# PIC32CK2051SG01100 register map
Vendor: Microchip Technology; Series: PIC32CKSG01; File version: 0
CPU: CM33 r0p0, little endian, MPU, FPU, DSP, 3 interrupt priority bits, 158 interrupts, 23 SAU regions
Registers are 32-bit, read-write, reset 0x0 unless marked. A register's access mark holds for its fields unless they carry their own. Offsets are from the block's base; [hi:lo] are bit positions; lines under a group give offsets from that group; {n}, {i} and the like mark numbered series; 'fields as' and 'values as' point back to an identical list.

## EBI — External Bus Interface
Base 0x4502C000; register names take the prefix EBI_
{0x0+0x10*i} CS_X[{i}] (i=0..3) group
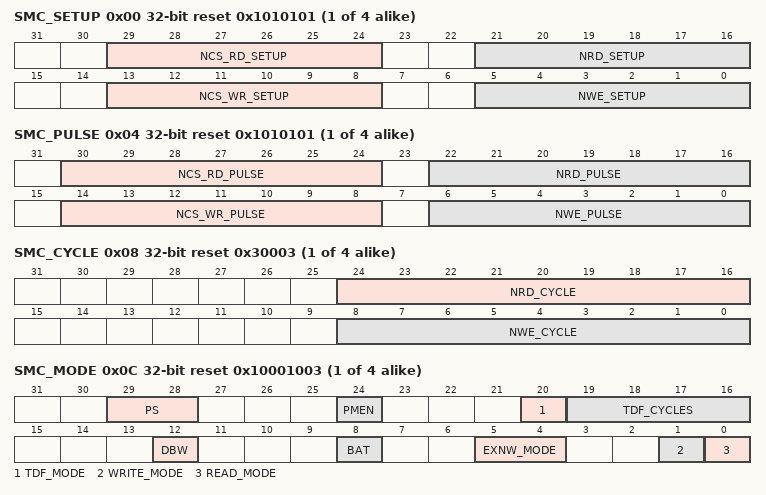
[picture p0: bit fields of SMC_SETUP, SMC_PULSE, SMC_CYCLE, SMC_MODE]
  0x00 SMC_SETUP reset 0x1010101
    [29:24] NCS_RD_SETUP — NCS Setup Length in READ Access
    [21:16] NRD_SETUP — NRD Setup Length
    [13:8] NCS_WR_SETUP — NCS Setup Length in WRITE Access
    [5:0] NWE_SETUP — NWE Setup Length
  0x04 SMC_PULSE reset 0x1010101
    [30:24] NCS_RD_PULSE — NCS Pulse Length in READ Access
    [22:16] NRD_PULSE — NRD Pulse Length
    [14:8] NCS_WR_PULSE — NCS Pulse Length in WRITE Access
    [6:0] NWE_PULSE — NWE Pulse Length
  0x08 SMC_CYCLE reset 0x30003
    [24:16] NRD_CYCLE — Total Read Cycle Length
    [8:0] NWE_CYCLE — Total Write Cycle Length
  0x0C SMC_MODE reset 0x10001003
    [29:28] PS — Page Size
      0=_4_BYTE (4-byte page); 1=_8_BYTE (8-byte page); 2=_16_BYTE (16-byte page); 3=_32_BYTE (32-byte page)
    [24] PMEN — Page Mode Enabled
    [20] TDF_MODE — TDF Optimization
    [19:16] TDF_CYCLES — Data Float Time
    [12] DBW — Data Bus Width
      0=_8_BIT (8-bit Data Bus); 1=_16_BIT (16-bit Data Bus)
    [8] BAT — Byte Access Type
      0=BYTE_SELECT (Byte select access type:- Write operation is controlled using NCS, NWE, NBS0, NBS1.- Read operation is controlled using NCS, NRD, NBS0, NBS1.); 1=BYTE_WRITE (Byte write access type:- Write operation is controlled using NCS, NWR0, NWR1.- Read operation is controlled using NCS and NRD.)
    [5:4] EXNW_MODE — NWAIT Mode
      0=DISABLED (Disabled-The NWAIT input signal is ignored on the corresponding chip select.); 2=FROZEN (Frozen Mode-If asserted, the NWAIT signal freezes the current read or write cycle. After deassertion, the read/write cycle is resumed from the point where it was stopped.); 3=READY (Ready Mode-The NWAIT signal indicates the availability of the external device at the end of the pulse of the controlling read or write signal, to complete the access. If high, the access normally completes. If low, the access is extended until NWAIT returns high.)
    [1] WRITE_MODE
    [0] READ_MODE
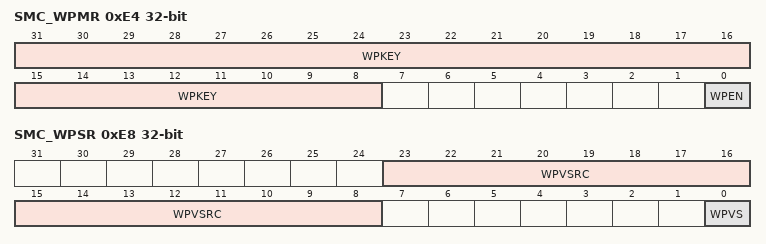
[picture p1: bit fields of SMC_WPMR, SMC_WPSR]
0xE4 SMC_WPMR — SMC Write Protection Mode Register
  [31:8] WPKEY — Write Protection Key
    0x534D43=PASSWD (Writing any other value in this field aborts the write operation of the WPEN bit. Always reads as 0.)
  [0] WPEN — Write Protect Enable
0xE8 SMC_WPSR ro — SMC Write Protection Status Register
  [23:8] WPVSRC — Write Protection Violation Source
  [0] WPVS — Write Protection Violation Status

## EIC — External Interrupt Controller
Base 0x4401A000; register names take the prefix EIC_
Same registers: EIC_SEC 0x4401B000 (register names take the prefix EIC_SEC_)
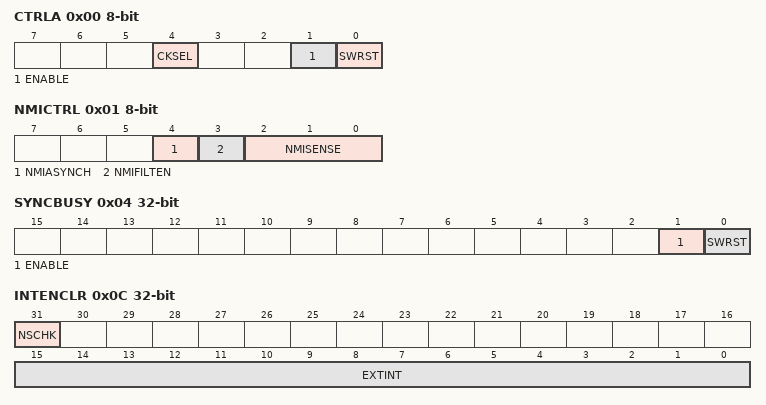
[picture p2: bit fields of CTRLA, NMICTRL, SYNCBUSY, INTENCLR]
0x00 CTRLA 8-bit — Control A
  [4] CKSEL — Clock Selection
    0=CLK_GCLK (Clocked by GCLK); 1=CLK_ULP32K (Clocked by ULP32K)
  [1] ENABLE
  [0] SWRST — Software Reset
0x01 NMICTRL 8-bit — Non-Maskable Interrupt Control
  [4] NMIASYNCH — Asynchronous Edge Detection Mode
    0=SYNC (Edge detection is clock synchronously operated); 1=ASYNC (Edge detection is clock asynchronously operated)
  [3] NMIFILTEN — Non-Maskable Interrupt Filter Enable
  [2:0] NMISENSE — Non-Maskable Interrupt Sense Configuration
    0=NONE (No detection); 1=RISE (Rising-edge detection); 2=FALL (Falling-edge detection); 3=BOTH (Both-edges detection); 4=HIGH (High-level detection); 5=LOW (Low-level detection)
0x02 NMIFLAG 16-bit — Non-Maskable Interrupt Flag Status and Clear
  [0] NMI — Non-Maskable Interrupt
0x04 SYNCBUSY ro — Synchronization Busy
  [1] ENABLE — Enable Synchronization Busy Status
  [0] SWRST — Software Reset Synchronization Busy Status
0x08 EVCTRL — Event Control
  [15:0] EXTINTEO — External Interrupt Event Output Enable
0x0C INTENCLR — Interrupt Enable Clear
  [31] NSCHK — Non-secure Check Interrupt Enable
  [15:0] EXTINT — External Interrupt Enable
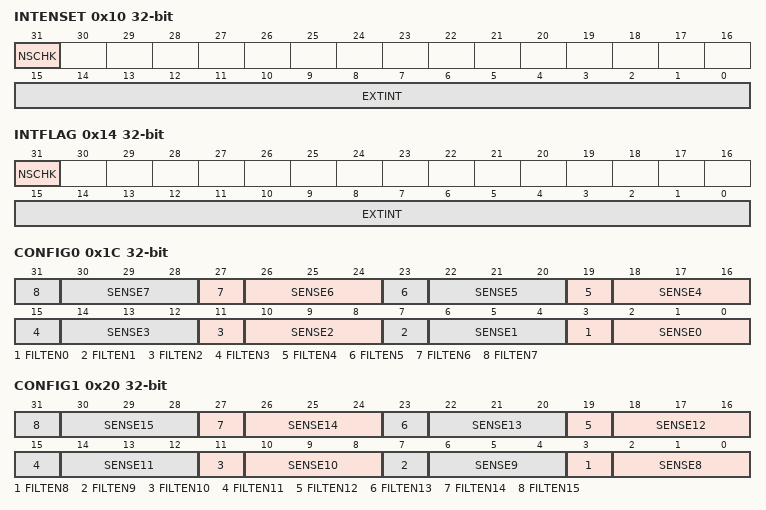
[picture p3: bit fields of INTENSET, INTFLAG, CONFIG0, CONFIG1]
0x10 INTENSET — Interrupt Enable Set
  fields as INTENCLR
0x14 INTFLAG — Interrupt Flag Status and Clear
  [31] NSCHK — Non-secure Check Interrupt
  [15:0] EXTINT — External Interrupt
0x18 ASYNCH — External Interrupt Asynchronous Mode
  [15:0] ASYNCH — Asynchronous Edge Detection Mode
    values as NMICTRL.NMIASYNCH
0x1C CONFIG0 — External Interrupt Sense Configuration
  [4n+3] FILTEN{n} (n=0..7) — Filter Enable {n}
  [4n+2:4n] SENSE{n} (n=0..7) — Input Sense Configuration {n}
    0=NONE (No detection); 1=RISE (Rising edge detection); 2=FALL (Falling edge detection); 3=BOTH (Both edges detection); 4=HIGH (High level detection); 5=LOW (Low level detection)
0x20 CONFIG1 — External Interrupt Sense Configuration
  [4n-29] FILTEN{n} (n=8..15) — Filter Enable {n}
  [4n-30:4n-32] SENSE{n} (n=8..15) — Input Sense Configuration {n}
    values as CONFIG0.SENSE0
0x30 DEBOUNCEN — Debouncer Enable
  [15:0] DEBOUNCEN
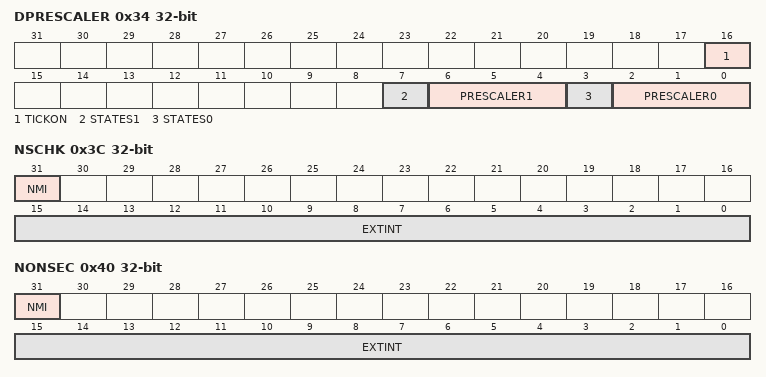
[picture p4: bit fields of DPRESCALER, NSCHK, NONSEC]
0x34 DPRESCALER — Debouncer Prescaler
  [16] TICKON — Pin Sampler frequency selection
    0=CLK_GCLK_EIC (Clocked by GCLK); 1=CLK_LFREQ (Clocked by Low Frequency Clock)
  [7] STATES1 — Debouncer number of states
    0=LFREQ3 (3 low frequency samples); 1=LFREQ7 (7 low frequency samples)
  [6:4] PRESCALER1 — Debouncer Prescaler
    0=DIV2 (EIC clock divided by 2); 1=DIV4 (EIC clock divided by 4); 2=DIV8 (EIC clock divided by 8); 3=DIV16 (EIC clock divided by 16); 4=DIV32 (EIC clock divided by 32); 5=DIV64 (EIC clock divided by 64); 6=DIV128 (EIC clock divided by 128); 7=DIV256 (EIC clock divided by 256)
  [3] STATES0 — Debouncer number of states
    values as STATES1
  [2:0] PRESCALER0 — Debouncer Prescaler
    values as PRESCALER1
0x38 PINSTATE ro
  [15:0] PINSTATE
0x3C NSCHK — Non-secure Interrupt Check Enable
  [31] NMI — Non-Maskable External Interrupt Nonsecure Check Enable
  [15:0] EXTINT — External Interrupt Nonsecure Check Enable
0x40 NONSEC — Non-secure Interrupt
  [31] NMI — Non-Maskable Interrupt Nonsecure Enable
  [15:0] EXTINT — External Interrupt Nonsecure Enable

## Notices in the file
Copyright (c) 2022 Microchip Technology Inc.
SPDX-License-Identifier: Apache-2.0
Licensed under the Apache License, Version 2.0 (the "License");
you may not use this file except in compliance with the License.
You may obtain a copy of the License at
http://www.apache.org/licenses/LICENSE-2.0
Unless required by applicable law or agreed to in writing, software
distributed under the License is distributed on an "AS IS" BASIS,
WITHOUT WARRANTIES OR CONDITIONS OF ANY KIND, either express or implied.
See the License for the specific language governing permissions and
limitations under the License.
